AUTOSAR XML (schema 4-2-2)
package /AUTOSAR_WdgM
  data type mapping set WdgM_Type_Map: mode-request-type-map{implementation-data-type=uint8, mode-group=WdgM_Mode}
  mode declaration group WdgM_Mode: category=EXPLICIT_ORDER, initial-mode=SUPERVISION_OK, on-transition-value=255
    5 x mode:
      SUPERVISION_OK: value=0
      SUPERVISION_FAILED: value=1
      SUPERVISION_EXPIRED: value=2
      SUPERVISION_STOPPED: value=3
      SUPERVISION_DEACTIVATED: value=4
  client server interface WdgM_LocalSupervision: is-service=true
    operation CheckpointReached: possible-error=[E_NOT_OK, E_OK]
    error E_OK: error-code=0
    error E_NOT_OK: error-code=1
  client server interface WdgM_LocalSupervisionStatus: is-service=true
    operation GetLocalStatus: possible-error=[E_NOT_OK, E_OK]
      arg Status: type=WdgM_LocalStatusType, direction=OUT
    error E_OK: error-code=0
    error E_NOT_OK: error-code=1
  client server interface WdgM_GlobalSupervision: is-service=true
    5 x operation:
      GetFirstExpiredSEID: possible-error=[E_NOT_OK, E_OK]
        arg SEID: type=WdgM_SupervisedEntityIdType, direction=OUT
      GetGlobalStatus: possible-error=[E_NOT_OK, E_OK]
        arg Status: type=WdgM_GlobalStatusType, direction=OUT
      GetMode: possible-error=[E_NOT_OK, E_OK]
        arg Mode: type=WdgM_ModeType, direction=OUT
      PerformReset
      SetMode: possible-error=[E_NOT_OK, E_OK]
        arg Mode: type=WdgM_ModeType, direction=IN
    error E_OK: error-code=0
    error E_NOT_OK: error-code=1
  mode switch interface WdgM_LocalMode: is-service=true
    mode group currentMode: type=WdgM_Mode
  mode switch interface WdgM_GlobalMode: is-service=true
    mode group currentMode: type=WdgM_Mode
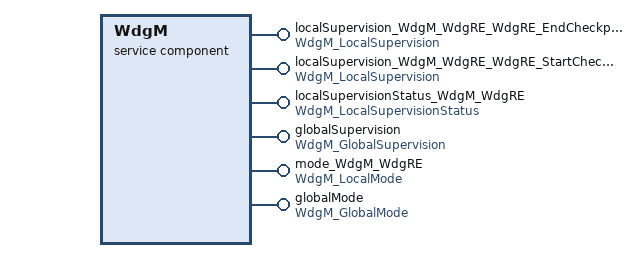
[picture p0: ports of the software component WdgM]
  service sw component type WdgM
    6 x provide port:
      localSupervision_WdgM_WdgRE_WdgRE_EndCheckpoint: server-com-spec{operation=CheckpointReached, queue-length=1}, provided-interface=WdgM_LocalSupervision
      localSupervision_WdgM_WdgRE_WdgRE_StartCheckpoint: server-com-spec{operation=CheckpointReached, queue-length=1}, provided-interface=WdgM_LocalSupervision
      localSupervisionStatus_WdgM_WdgRE: server-com-spec{operation=GetLocalStatus, queue-length=1}, provided-interface=WdgM_LocalSupervisionStatus
      globalSupervision: provided-interface=WdgM_GlobalSupervision
        provided-com-specs:
          operation=GetFirstExpiredSEID, queue-length=1
          operation=GetGlobalStatus, queue-length=1
          operation=GetMode, queue-length=1
          operation=PerformReset, queue-length=1
          operation=SetMode, queue-length=1
      mode_WdgM_WdgRE: mode-switch-sender-com-spec{mode-group=currentMode, mode-switched-ack=timeout=1.0, queue-length=1}, provided-interface=WdgM_LocalMode
      globalMode: mode-switch-sender-com-spec{mode-group=currentMode, mode-switched-ack=timeout=1.0, queue-length=1}, provided-interface=WdgM_GlobalMode
    behavior WdgM_InternalBehaviour: data-type-mapping=WdgM_Type_Map
      8 x operation invoked event:
        OIE_CheckpointReached_WdgM_WdgRE_WdgRE_EndCheckpoint: start-on-event=CheckpointReached, operation=localSupervision_WdgM_WdgRE_WdgRE_EndCheckpoint.CheckpointReached
        OIE_CheckpointReached_WdgM_WdgRE_WdgRE_StartCheckpoint: start-on-event=CheckpointReached, operation=localSupervision_WdgM_WdgRE_WdgRE_StartCheckpoint.CheckpointReached
        OIE_GetLocalStatus_WdgM_WdgRE: start-on-event=GetLocalStatus, operation=localSupervisionStatus_WdgM_WdgRE.GetLocalStatus
        OIE_GetFirstExpiredSEID: start-on-event=GetFirstExpiredSEID, operation=globalSupervision.GetFirstExpiredSEID
        OIE_GetGlobalStatus: start-on-event=GetGlobalStatus, operation=globalSupervision.GetGlobalStatus
        OIE_GetMode: start-on-event=GetMode, operation=globalSupervision.GetMode
        OIE_PerformReset: start-on-event=PerformReset, operation=globalSupervision.PerformReset
        OIE_SetMode: start-on-event=SetMode, operation=globalSupervision.SetMode
      port-api-options:
        {enable-take-address=false, indirect-api=false, port-arg-values=[{value=0, value-type=WdgM_SupervisedEntityIdType}, {value=0, value-type=WdgM_CheckpointIdType}], port=localSupervision_WdgM_WdgRE_WdgRE_EndCheckpoint}
        {enable-take-address=false, indirect-api=false, port-arg-values=[{value=0, value-type=WdgM_SupervisedEntityIdType}, {value=1, value-type=WdgM_CheckpointIdType}], port=localSupervision_WdgM_WdgRE_WdgRE_StartCheckpoint}
        {enable-take-address=false, indirect-api=false, port-defined-argument-value{value=0, value-type=WdgM_SupervisedEntityIdType}, port=localSupervisionStatus_WdgM_WdgRE}
        enable-take-address=false, indirect-api=false, port=globalSupervision
        indirect-api=true, port=mode_WdgM_WdgRE
        enable-take-address=true, indirect-api=false, port=globalMode
      8 x runnable:
        CheckpointReached: sw-addr-method=CODE_FAST, arguments=[symbol=SEID, symbol=CheckpointID], can-be-invoked-concurrently=true, symbol=WdgM_CheckpointReached
        GetLocalStatus: sw-addr-method=CODE_FAST, arguments=[symbol=SEID, symbol=Status], can-be-invoked-concurrently=true, symbol=WdgM_GetLocalStatus
        GetFirstExpiredSEID: sw-addr-method=CODE_SLOW, runnable-entity-argument=symbol=SEID, can-be-invoked-concurrently=true, symbol=WdgM_GetFirstExpiredSEID
        GetGlobalStatus: sw-addr-method=CODE_FAST, runnable-entity-argument=symbol=Status, can-be-invoked-concurrently=true, symbol=WdgM_GetGlobalStatus
        GetMode: sw-addr-method=CODE_FAST, runnable-entity-argument=symbol=Mode, can-be-invoked-concurrently=true, symbol=WdgM_GetMode
        PerformReset: sw-addr-method=CODE_FAST, can-be-invoked-concurrently=true, symbol=WdgM_PerformReset
        SetMode: sw-addr-method=CODE_FAST, runnable-entity-argument=symbol=Mode, can-be-invoked-concurrently=true, symbol=WdgM_SetMode
        MainFunction: symbol=WdgM_MainFunction
          mode switch point msp_WdgM_LocalMode_WdgM_WdgRE: mode-group=mode_WdgM_WdgRE.currentMode
          mode switch point msp_WdgM_GlobalMode: mode-group=globalMode.currentMode
package /SwcImplementations
  swc implementation WdgM: programming-language=C, sw-version=8.1.0, vendor-id=6, behavior=WdgM_InternalBehaviour
    code-descriptors:
      code CodeDescriptor: artifact-descriptors=autosar-engineering-object={short-label=ArEngObj, category=SWSRC}
